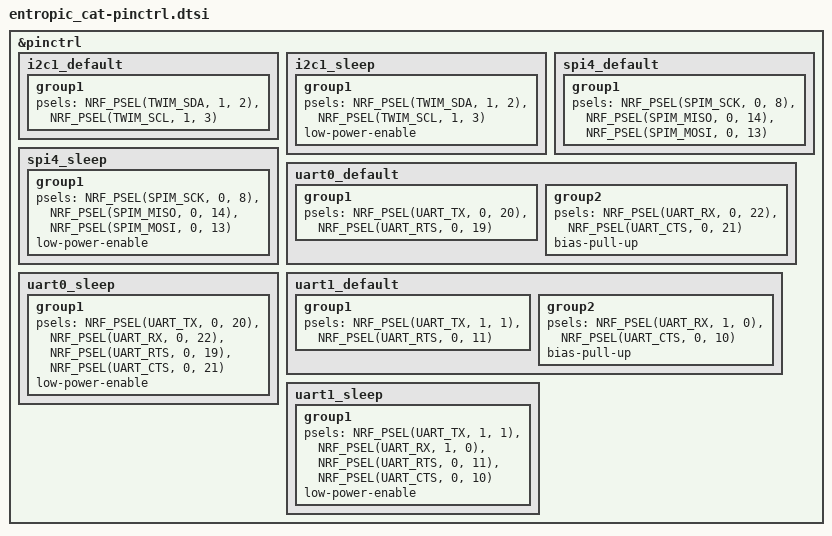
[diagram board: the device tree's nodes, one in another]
&pinctrl {
	i2c1_default: i2c1_default {
		group1 {
			psels = <NRF_PSEL(TWIM_SDA, 1, 2)>,
				<NRF_PSEL(TWIM_SCL, 1, 3)>;
		};
	};

	i2c1_sleep: i2c1_sleep {
		group1 {
			psels = <NRF_PSEL(TWIM_SDA, 1, 2)>,
				<NRF_PSEL(TWIM_SCL, 1, 3)>;
			low-power-enable;
		};
	};

	spi4_default: spi4_default {
		group1 {
			psels = <NRF_PSEL(SPIM_SCK, 0, 8)>,
				<NRF_PSEL(SPIM_MISO, 0, 14)>,
				<NRF_PSEL(SPIM_MOSI, 0, 13)>;
		};
	};

	spi4_sleep: spi4_sleep {
		group1 {
			psels = <NRF_PSEL(SPIM_SCK, 0, 8)>,
				<NRF_PSEL(SPIM_MISO, 0, 14)>,
				<NRF_PSEL(SPIM_MOSI, 0, 13)>;
			low-power-enable;
		};
	};

    /* The following are defaults from nrf5340-dk, TO BE UPDATED! */

	uart0_default: uart0_default {
		group1 {
			psels = <NRF_PSEL(UART_TX, 0, 20)>,
				<NRF_PSEL(UART_RTS, 0, 19)>;
		};
		group2 {
			psels = <NRF_PSEL(UART_RX, 0, 22)>,
				<NRF_PSEL(UART_CTS, 0, 21)>;
			bias-pull-up;
		};
	};

	uart0_sleep: uart0_sleep {
		group1 {
			psels = <NRF_PSEL(UART_TX, 0, 20)>,
				<NRF_PSEL(UART_RX, 0, 22)>,
				<NRF_PSEL(UART_RTS, 0, 19)>,
				<NRF_PSEL(UART_CTS, 0, 21)>;
			low-power-enable;
		};
	};

	uart1_default: uart1_default {
		group1 {
			psels = <NRF_PSEL(UART_TX, 1, 1)>,
				<NRF_PSEL(UART_RTS, 0, 11)>;
		};
		group2 {
			psels = <NRF_PSEL(UART_RX, 1, 0)>,
				<NRF_PSEL(UART_CTS, 0, 10)>;
			bias-pull-up;
		};
	};

	uart1_sleep: uart1_sleep {
		group1 {
			psels = <NRF_PSEL(UART_TX, 1, 1)>,
				<NRF_PSEL(UART_RX, 1, 0)>,
				<NRF_PSEL(UART_RTS, 0, 11)>,
				<NRF_PSEL(UART_CTS, 0, 10)>;
			low-power-enable;
		};
	};
};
